# GD32F3x0 register map
File version: 1.0
CPU: CM4 r2p1, little endian, no MPU, no FPU, 4 interrupt priority bits
Registers are 32-bit, read-write, reset 0x0 unless marked. A register's access mark holds for its fields unless they carry their own. Offsets are from the block's base; [hi:lo] are bit positions; {n}, {i} and the like mark numbered series.

## NVIC — Nested Vectored Interrupt Controller
Base 0xE000E100
0x00 ISER — Interrupt Set Enable Register
  [31:0] SETENA
0x80 ICER — Interrupt Clear Enable Register
  [31:0] CLRENA
0x100 ISPR — Interrupt Set-Pending Register
  [31:0] SETPEND
0x180 ICPR — Interrupt Clear-Pending Register
  [31:0] CLRPEND
0x200 IABR — Interrupt Active bit Register
{0x300+i} IPR{i} 8-bit (i=0..73) — Interrupt Priority Register {i}
  [7:0] PRI_{i:02}
0xE00 STIR wo — Software Trigger Interrupt Register

## PMU — Power management unit
Base 0x40007000
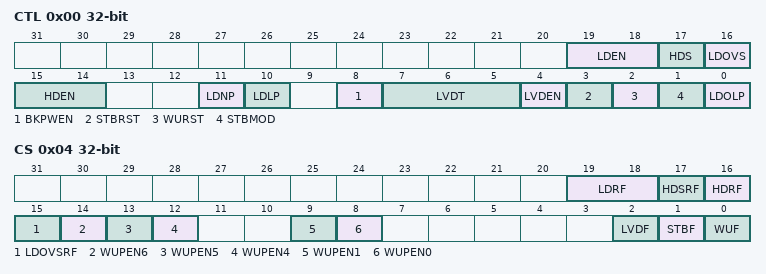
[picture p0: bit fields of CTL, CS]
0x00 CTL — power control register
  [19:18] LDEN — Low-driver mode enable in Deep-sleep mode
  [17] HDS — High-driver mode switch
  [16] LDOVS — LDO output voltage select
  [15:14] HDEN — High-driver mode enable
  [11] LDNP — Low-driver mode when use normal power LDO
  [10] LDLP — Low-driver mode when use low power LDO
  [8] BKPWEN — Backup Domain Write Enable
  [7:5] LVDT — Low Voltage Detector Threshold
  [4] LVDEN — Low Voltage Detector Enable
  [3] STBRST — Standby Flag Reset
  [2] WURST — Wakeup Flag Reset
  [1] STBMOD — Standby Mode
  [0] LDOLP — LDO Low Power Mode
0x04 CS access per field — power control/status register
  [19:18] LDRF rw — Low-driver mode ready flag
  [17] HDSRF rw — High-driver switch ready flag
  [16] HDRF rw — High-driver ready flag
  [15] LDOVSRF rw — LDO voltage select ready flag
  [14] WUPEN6 rw — WKUP pin6 Enable
  [13] WUPEN5 rw — WKUP pin5 Enable
  [12] WUPEN4 rw — WKUP pin4 Enable
  [9] WUPEN1 rw — WKUP pin1 Enable
  [8] WUPEN0 rw — WKUP pin0 Enable
  [2] LVDF ro — Low Voltage Detector Status Flag
  [1] STBF ro — Standby flag
  [0] WUF ro — Wakeup flag

## SPI0 — Serial peripheral interface
Base 0x40013000
Same registers: SPI1 0x40003800, SPI2 0x40003C00
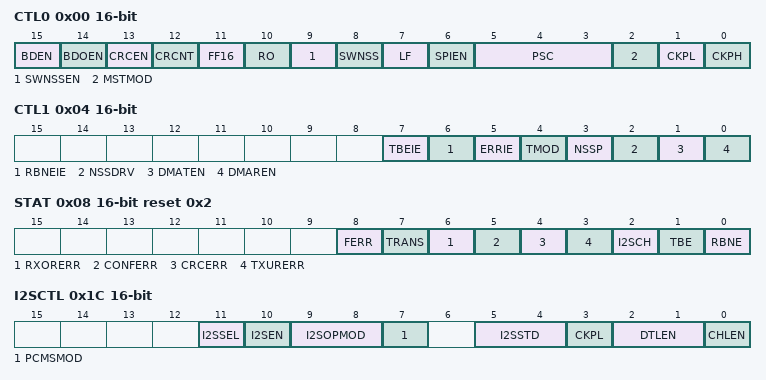
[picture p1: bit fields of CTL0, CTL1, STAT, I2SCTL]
0x00 CTL0 16-bit — control register 0
  [15] BDEN — Bidirectional enable
  [14] BDOEN — Bidirectional Transmit output enable
  [13] CRCEN — Hardware CRC calculation enable
  [12] CRCNT — CRC transfer next
  [11] FF16 — Data frame format
  [10] RO — Receive only
  [9] SWNSSEN — NSS Software Mode Selection
  [8] SWNSS — NSS Pin Selection In NSS Software Mode
  [7] LF — LSB First Mode
  [6] SPIEN — SPI enable
  [5:3] PSC — Master Clock Prescaler Selection
  [2] MSTMOD — Master Mode Enable
  [1] CKPL — Clock Polarity Selection
  [0] CKPH — Clock Phase Selection
0x04 CTL1 16-bit — control register 1
  [7] TBEIE — Transmit Buffer Empty Interrupt Enable
  [6] RBNEIE — Receive Buffer Not Empty Interrupt Enable
  [5] ERRIE — Error interrupt enable
  [4] TMOD — SPI TI Mode Enable
  [3] NSSP — SPI NSS Pulse Mode Enable
  [2] NSSDRV — NSS output enable
  [1] DMATEN — Tx buffer DMA enable
  [0] DMAREN — Rx buffer DMA enable
0x08 STAT 16-bit access per field reset 0x2 — status register
  [8] FERR ro — Format Error
  [7] TRANS ro — Transmitting On-going Bit
  [6] RXORERR ro — Reception Overrun Error Bit
  [5] CONFERR ro — SPI Configuration error
  [4] CRCERR rw — SPI CRC Error Bit
  [3] TXURERR ro — Transmission underrun error bit
  [2] I2SCH ro — I2S channel side
  [1] TBE ro — Transmit Buffer Empty
  [0] RBNE ro — Receive Buffer Not Empty
0x0C DATA 16-bit
0x10 CPCPOLY 16-bit reset 0x7 — CRC polynomial register
  [15:0] CPR
0x14 RCRC 16-bit ro — RX CRC register
  [15:0] RCR — RX RCR register
0x18 TCRC 16-bit ro — TX CRC register
  [15:0] TCR — Tx CRC register
0x1C I2SCTL 16-bit — I2S configuration register
  [11] I2SSEL — I2S mode selection
  [10] I2SEN — I2S Enable
  [9:8] I2SOPMOD — I2S configuration mode
  [7] PCMSMOD — PCM frame synchronization
  [5:4] I2SSTD — I2S standard selection
  [3] CKPL — Idle state clock polarity
  [2:1] DTLEN — Data length to be transferred
  [0] CHLEN — Channel length (number of bits per audio channel)
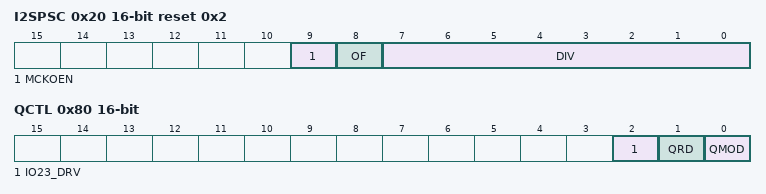
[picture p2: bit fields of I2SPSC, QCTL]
0x20 I2SPSC 16-bit reset 0x2 — I2S prescaler register
  [9] MCKOEN — I2S_MCK output enable
  [8] OF — Odd factor for the prescaler
  [7:0] DIV — Dividing factor for the prescaler
0x80 QCTL 16-bit — SPI quad wird control register
  [2] IO23_DRV — Drive IO2 and IO3 enable
  [1] QRD — Quad wire read select
  [0] QMOD — Quad wire mode enable
